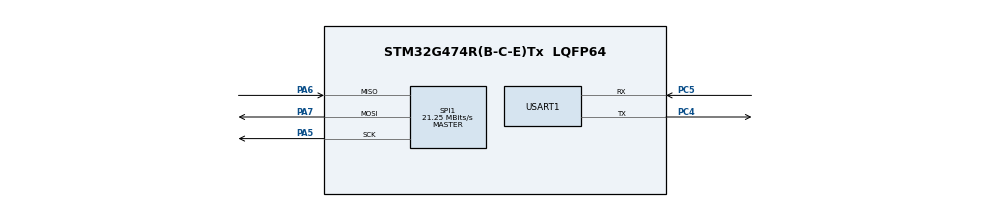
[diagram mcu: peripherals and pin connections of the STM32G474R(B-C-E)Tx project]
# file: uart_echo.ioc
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Dma.Request0=USART1_RX
Dma.Request1=USART1_TX
Dma.USART1_RX.0.Direction=DMA_PERIPH_TO_MEMORY
Dma.USART1_RX.0.EventEnable=DISABLE
Dma.USART1_RX.0.Instance=DMA2_Channel2
Dma.USART1_RX.0.MemDataAlignment=DMA_MDATAALIGN_BYTE
Dma.USART1_RX.0.MemInc=DMA_MINC_ENABLE
Dma.USART1_RX.0.Mode=DMA_CIRCULAR
Dma.USART1_RX.0.PeriphDataAlignment=DMA_PDATAALIGN_BYTE
Dma.USART1_RX.0.PeriphInc=DMA_PINC_DISABLE
Dma.USART1_RX.0.Polarity=HAL_DMAMUX_REQ_GEN_RISING
Dma.USART1_RX.0.Priority=DMA_PRIORITY_HIGH
Dma.USART1_RX.0.RequestNumber=1
Dma.USART1_RX.0.SignalID=NONE
Dma.USART1_RX.0.SyncEnable=DISABLE
Dma.USART1_RX.0.SyncPolarity=HAL_DMAMUX_SYNC_NO_EVENT
Dma.USART1_RX.0.SyncRequestNumber=1
Dma.USART1_RX.0.SyncSignalID=NONE
Dma.USART1_TX.1.Direction=DMA_MEMORY_TO_PERIPH
Dma.USART1_TX.1.EventEnable=DISABLE
Dma.USART1_TX.1.Instance=DMA1_Channel1
Dma.USART1_TX.1.MemDataAlignment=DMA_MDATAALIGN_BYTE
Dma.USART1_TX.1.MemInc=DMA_MINC_ENABLE
Dma.USART1_TX.1.Mode=DMA_NORMAL
Dma.USART1_TX.1.PeriphDataAlignment=DMA_PDATAALIGN_BYTE
Dma.USART1_TX.1.PeriphInc=DMA_PINC_DISABLE
Dma.USART1_TX.1.Polarity=HAL_DMAMUX_REQ_GEN_RISING
Dma.USART1_TX.1.Priority=DMA_PRIORITY_HIGH
Dma.USART1_TX.1.RequestNumber=1
Dma.USART1_TX.1.SignalID=NONE
Dma.USART1_TX.1.SyncEnable=DISABLE
Dma.USART1_TX.1.SyncPolarity=HAL_DMAMUX_SYNC_NO_EVENT
Dma.USART1_TX.1.SyncRequestNumber=1
Dma.USART1_TX.1.SyncSignalID=NONE
FREERTOS.Tasks01=defaultTask,0,128,StartDefaultTask,Default,NULL,Dynamic,NULL,NULL
FREERTOS.configGENERATE_RUN_TIME_STATS=1
FREERTOS.configRECORD_STACK_HIGH_ADDRESS=1
FREERTOS.configUSE_NEWLIB_REENTRANT=1
FREERTOS.configUSE_TRACE_FACILITY=1
Mcu.Family=STM32G4
Mcu.Name=STM32G474R(B-C-E)Tx
Mcu.Package=LQFP64
NVIC.DMA1_Channel1_IRQn=true\:5\:0\:false\:false\:true\:false\:false\:true\:true
NVIC.DMA2_Channel2_IRQn=true\:5\:0\:false\:false\:true\:true\:false\:true\:true
NVIC.PriorityGroup=NVIC_PRIORITYGROUP_4
NVIC.TIM20_UP_IRQn=true\:15\:0\:false\:false\:true\:false\:false\:true\:true
NVIC.TimeBase=TIM20_UP_IRQn
NVIC.TimeBaseIP=TIM20
NVIC.USART1_IRQn=true\:5\:0\:false\:false\:true\:true\:true\:true\:true
PA13.Mode=Trace_Asynchronous_SW
PA13.Signal=SYS_JTMS-SWDIO
PA14.Mode=Trace_Asynchronous_SW
PA14.Signal=SYS_JTCK-SWCLK
PA5.Mode=Full_Duplex_Master
PA5.Signal=SPI1_SCK
PA6.Mode=Full_Duplex_Master
PA6.Signal=SPI1_MISO
PA7.Mode=Full_Duplex_Master
PA7.Signal=SPI1_MOSI
PB3.Mode=Trace_Asynchronous_SW
PB3.Signal=SYS_JTDO-SWO
PC4.Mode=Asynchronous
PC4.Signal=USART1_TX
PC5.Mode=Asynchronous
PC5.Signal=USART1_RX
PF0-OSC_IN.Mode=HSE-External-Oscillator
PF0-OSC_IN.Signal=RCC_OSC_IN
PF1-OSC_OUT.Mode=HSE-External-Oscillator
PF1-OSC_OUT.Signal=RCC_OSC_OUT
ProjectManager.HeapSize=0x200
ProjectManager.StackSize=0x400
ProjectManager.TargetToolchain=STM32CubeIDE
RCC.ADC12Freq_Value=170000000
RCC.ADC345Freq_Value=170000000
RCC.AHBFreq_Value=170000000
RCC.APB1Freq_Value=170000000
RCC.APB1TimFreq_Value=170000000
RCC.APB2Freq_Value=170000000
RCC.APB2TimFreq_Value=170000000
RCC.CortexFreq_Value=170000000
RCC.EXTERNAL_CLOCK_VALUE=12288000
RCC.HCLKFreq_Value=170000000
RCC.HSE_VALUE=24000000
RCC.HSI48_VALUE=48000000
RCC.HSI_VALUE=16000000
RCC.LSE_VALUE=32768
RCC.PLLM=RCC_PLLM_DIV6
RCC.PLLN=85
RCC.PLLSourceVirtual=RCC_PLLSOURCE_HSE
RCC.SYSCLKFreq_VALUE=170000000
RCC.SYSCLKSource=RCC_SYSCLKSOURCE_PLLCLK
RCC.USBFreq_Value=170000000
RCC.VCOOutputFreq_Value=340000000
SPI1.BaudRatePrescaler=SPI_BAUDRATEPRESCALER_8
SPI1.CalculateBaudRate=21.25 MBits/s
SPI1.DataSize=SPI_DATASIZE_8BIT
SPI1.Direction=SPI_DIRECTION_2LINES
SPI1.Mode=SPI_MODE_MASTER
SPI1.VirtualType=VM_MASTER
TIM7.Prescaler=170-1
USART1.VirtualMode-Asynchronous=VM_ASYNC
VP_FREERTOS_VS_CMSIS_V1.Mode=CMSIS_V1
VP_SYS_VS_DBSignals.Mode=DisableDeadBatterySignals
VP_SYS_VS_tim20.Mode=TIM20
VP_TIM7_VS_ClockSourceINT.Mode=Enable_Timer
board=custom

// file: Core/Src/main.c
/* USER CODE BEGIN Header */
/**
  ******************************************************************************
  * @file           : main.c
  * @brief          : Main program body
  ******************************************************************************
  * @attention
  *
  * Copyright (c) 2023 STMicroelectronics.
  * All rights reserved.
  *
  * This software is licensed under terms that can be found in the LICENSE file
  * in the root directory of this software component.
  * If no LICENSE file comes with this software, it is provided AS-IS.
  *
  ******************************************************************************
  */
/* USER CODE END Header */
#include "main.h"
#include "cmsis_os.h"
#include "dma.h"
#include "spi.h"
#include "tim.h"
#include "usart.h"
#include "gpio.h"

/* USER CODE BEGIN Includes */
#include "user_freertos.h"
/* USER CODE END Includes */

void SystemClock_Config(void);
void MX_FREERTOS_Init(void);

/* USER CODE BEGIN 0 */
int _write(int file, char *ptr, int len)
{
  /* Implement your write code here, this is used by puts and printf for example */
  int i=0;
  for(i=0 ; i<len ; i++)
    ITM_SendChar((*ptr++));
  return len;
}
/* USER CODE END 0 */

int main(void)
{

  /* MCU Configuration--------------------------------------------------------*/

  /* Reset of all peripherals, Initializes the Flash interface and the Systick. */
  HAL_Init();

  /* Configure the system clock */
  SystemClock_Config();

  /* Initialize all configured peripherals */
  MX_GPIO_Init();
  MX_DMA_Init();
  MX_SPI1_Init();
  MX_USART1_UART_Init();
  MX_TIM7_Init();
  /* USER CODE BEGIN 2 */
  /* Call init function for freertos objects (in user_freertos.c) */
  freertos_init();
  /* USER CODE END 2 */
  /* Start scheduler */
  osKernelStart();

  /* We should never get here as control is now taken by the scheduler */
  /* Infinite loop */
  while (1)
  {

  }
}

void SystemClock_Config(void)
{
  LL_FLASH_SetLatency(LL_FLASH_LATENCY_4);
  while(LL_FLASH_GetLatency() != LL_FLASH_LATENCY_4)
  {
  }
  LL_PWR_EnableRange1BoostMode();
  LL_RCC_HSE_Enable();
   /* Wait till HSE is ready */
  while(LL_RCC_HSE_IsReady() != 1)
  {
  }

  LL_RCC_PLL_ConfigDomain_SYS(LL_RCC_PLLSOURCE_HSE, LL_RCC_PLLM_DIV_6, 85, LL_RCC_PLLR_DIV_2);
  LL_RCC_PLL_EnableDomain_SYS();
  LL_RCC_PLL_Enable();
   /* Wait till PLL is ready */
  while(LL_RCC_PLL_IsReady() != 1)
  {
  }

  LL_RCC_SetSysClkSource(LL_RCC_SYS_CLKSOURCE_PLL);
  LL_RCC_SetAHBPrescaler(LL_RCC_SYSCLK_DIV_2);
   /* Wait till System clock is ready */
  while(LL_RCC_GetSysClkSource() != LL_RCC_SYS_CLKSOURCE_STATUS_PLL)
  {
  }

  /* Insure 1us transition state at intermediate medium speed clock*/
  for (__IO uint32_t i = (170 >> 1); i !=0; i--);

  /* Set AHB prescaler*/
  LL_RCC_SetAHBPrescaler(LL_RCC_SYSCLK_DIV_1);
  LL_RCC_SetAPB1Prescaler(LL_RCC_APB1_DIV_1);
  LL_RCC_SetAPB2Prescaler(LL_RCC_APB2_DIV_1);
  LL_SetSystemCoreClock(170000000);

   /* Update the time base */
  if (HAL_InitTick (TICK_INT_PRIORITY) != HAL_OK)
  {
    Error_Handler();
  }
}

void HAL_TIM_PeriodElapsedCallback(TIM_HandleTypeDef *htim)
{
  if (htim->Instance == TIM20) {
    HAL_IncTick();
  }
}

void Error_Handler(void)
{
  __disable_irq();
  while (1)
  {
  }
}
